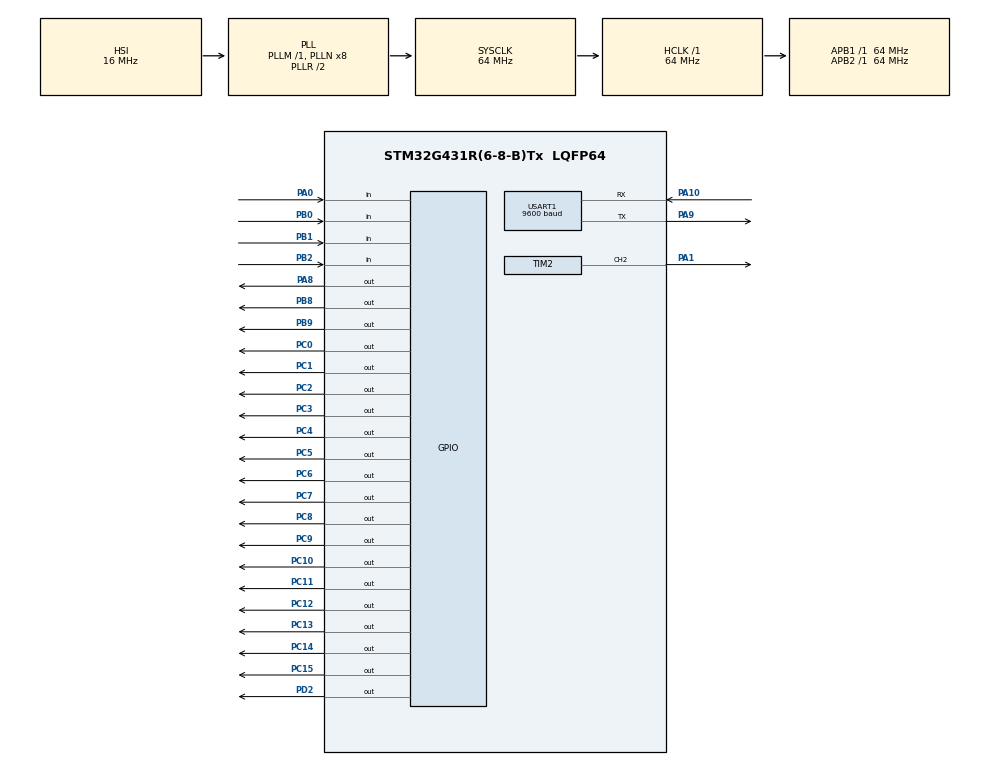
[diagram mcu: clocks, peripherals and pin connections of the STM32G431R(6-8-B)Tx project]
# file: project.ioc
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Mcu.Family=STM32G4
Mcu.Name=STM32G431R(6-8-B)Tx
Mcu.Package=LQFP64
NVIC.PriorityGroup=NVIC_PRIORITYGROUP_4
NVIC.USART1_IRQn=true\:0\:0\:false\:false\:true\:true\:true
PA0.GPIO_PuPd=GPIO_PULLUP
PA0.Signal=GPIO_Input
PA1.Signal=S_TIM2_CH2
PA10.Mode=Asynchronous
PA10.Signal=USART1_RX
PA8.Signal=GPIO_Output
PA9.Mode=Asynchronous
PA9.Signal=USART1_TX
PB0.GPIO_PuPd=GPIO_PULLUP
PB0.Signal=GPIO_Input
PB1.GPIO_PuPd=GPIO_PULLUP
PB1.Signal=GPIO_Input
PB2.GPIO_PuPd=GPIO_PULLUP
PB2.Signal=GPIO_Input
PB8-BOOT0.Signal=GPIO_Output
PB9.Signal=GPIO_Output
PC0.Signal=GPIO_Output
PC1.Signal=GPIO_Output
PC10.Signal=GPIO_Output
PC11.Signal=GPIO_Output
PC12.Signal=GPIO_Output
PC13.Signal=GPIO_Output
PC14-OSC32_IN.Signal=GPIO_Output
PC15-OSC32_OUT.Signal=GPIO_Output
PC2.Signal=GPIO_Output
PC3.Signal=GPIO_Output
PC4.Signal=GPIO_Output
PC5.Signal=GPIO_Output
PC6.Signal=GPIO_Output
PC7.Signal=GPIO_Output
PC8.Signal=GPIO_Output
PC9.Signal=GPIO_Output
PD2.Signal=GPIO_Output
PF0-OSC_IN.Mode=HSE-External-Oscillator
PF0-OSC_IN.Signal=RCC_OSC_IN
PF1-OSC_OUT.Mode=HSE-External-Oscillator
PF1-OSC_OUT.Signal=RCC_OSC_OUT
ProjectManager.HeapSize=0x200
ProjectManager.StackSize=0x400
ProjectManager.TargetToolchain=MDK-ARM V5.32
RCC.ADC12Freq_Value=64000000
RCC.AHBFreq_Value=64000000
RCC.APB1Freq_Value=64000000
RCC.APB1TimFreq_Value=64000000
RCC.APB2Freq_Value=64000000
RCC.APB2TimFreq_Value=64000000
RCC.CortexFreq_Value=64000000
RCC.EXTERNAL_CLOCK_VALUE=12288000
RCC.HCLKFreq_Value=64000000
RCC.HSE_VALUE=8000000
RCC.HSI48_VALUE=48000000
RCC.HSI_VALUE=16000000
RCC.LSE_VALUE=32768
RCC.SYSCLKFreq_VALUE=64000000
RCC.SYSCLKSource=RCC_SYSCLKSOURCE_PLLCLK
RCC.USBFreq_Value=64000000
RCC.VCOOutputFreq_Value=128000000
SH.S_TIM2_CH2.0=TIM2_CH2,PWM Generation2 CH2
TIM2.Channel-PWM\ Generation2\ CH2=TIM_CHANNEL_2
TIM2.PeriodNoDither=500-1
TIM2.Prescaler=64-1
USART1.BaudRate=9600
USART1.VirtualMode-Asynchronous=VM_ASYNC
VP_SYS_VS_DBSignals.Mode=DisableDeadBatterySignals
VP_TIM2_VS_ClockSourceINT.Mode=Internal
board=custom

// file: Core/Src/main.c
/* USER CODE BEGIN Header */
/**
  ******************************************************************************
  * @file           : main.c
  * @brief          : Main program body
  ******************************************************************************
  * @attention
  *
  * Copyright (c) 2022 STMicroelectronics.
  * All rights reserved.
  *
  * This software is licensed under terms that can be found in the LICENSE file
  * in the root directory of this software component.
  * If no LICENSE file comes with this software, it is provided AS-IS.
  *
  ******************************************************************************
  */
/* USER CODE END Header */
#include "main.h"

TIM_HandleTypeDef htim2;

UART_HandleTypeDef huart1;

/* USER CODE BEGIN PV */
extern char rec[1];
/* USER CODE END PV */

void SystemClock_Config(void);
static void MX_GPIO_Init(void);
static void MX_TIM2_Init(void);
static void MX_USART1_UART_Init(void);

int main(void)
{

  /* MCU Configuration--------------------------------------------------------*/

  /* Reset of all peripherals, Initializes the Flash interface and the Systick. */
  HAL_Init();

  /* Configure the system clock */
  SystemClock_Config();

  /* Initialize all configured peripherals */
  MX_GPIO_Init();
  MX_TIM2_Init();
  MX_USART1_UART_Init();
  /* USER CODE BEGIN 2 */
	I2CInit();
	//EE_init();
	HAL_TIM_PWM_Start(&htim2,TIM_CHANNEL_2);
	LCD_Init();
	LCD_SetTextColor(White);
	LCD_SetBackColor(Black);
	HAL_UART_Receive_IT(&huart1,(unsigned char*)rec,1);
  /* USER CODE END 2 */

  /* Infinite loop */
  while (1)
  {

    /* USER CODE BEGIN 3 */
		EE_rd();
		key_menu();
		lcd_menu();
		pwm_main();
		led_main();
  }
  /* USER CODE END 3 */
}

void SystemClock_Config(void)
{
  RCC_OscInitTypeDef RCC_OscInitStruct = {0};
  RCC_ClkInitTypeDef RCC_ClkInitStruct = {0};

  /** Configure the main internal regulator output voltage
  */
  HAL_PWREx_ControlVoltageScaling(PWR_REGULATOR_VOLTAGE_SCALE1);
  /** Initializes the RCC Oscillators according to the specified parameters
  * in the RCC_OscInitTypeDef structure.
  */
  RCC_OscInitStruct.OscillatorType = RCC_OSCILLATORTYPE_HSI;
  RCC_OscInitStruct.HSIState = RCC_HSI_ON;
  RCC_OscInitStruct.HSICalibrationValue = RCC_HSICALIBRATION_DEFAULT;
  RCC_OscInitStruct.PLL.PLLState = RCC_PLL_ON;
  RCC_OscInitStruct.PLL.PLLSource = RCC_PLLSOURCE_HSI;
  RCC_OscInitStruct.PLL.PLLM = RCC_PLLM_DIV1;
  RCC_OscInitStruct.PLL.PLLN = 8;
  RCC_OscInitStruct.PLL.PLLP = RCC_PLLP_DIV2;
  RCC_OscInitStruct.PLL.PLLQ = RCC_PLLQ_DIV2;
  RCC_OscInitStruct.PLL.PLLR = RCC_PLLR_DIV2;
  if (HAL_RCC_OscConfig(&RCC_OscInitStruct) != HAL_OK)
  {
    Error_Handler();
  }
  /** Initializes the CPU, AHB and APB buses clocks
  */
  RCC_ClkInitStruct.ClockType = RCC_CLOCKTYPE_HCLK|RCC_CLOCKTYPE_SYSCLK
                              |RCC_CLOCKTYPE_PCLK1|RCC_CLOCKTYPE_PCLK2;
  RCC_ClkInitStruct.SYSCLKSource = RCC_SYSCLKSOURCE_PLLCLK;
  RCC_ClkInitStruct.AHBCLKDivider = RCC_SYSCLK_DIV1;
  RCC_ClkInitStruct.APB1CLKDivider = RCC_HCLK_DIV1;
  RCC_ClkInitStruct.APB2CLKDivider = RCC_HCLK_DIV1;

  if (HAL_RCC_ClockConfig(&RCC_ClkInitStruct, FLASH_LATENCY_1) != HAL_OK)
  {
    Error_Handler();
  }
}

static void MX_TIM2_Init(void)
{

  TIM_ClockConfigTypeDef sClockSourceConfig = {0};
  TIM_MasterConfigTypeDef sMasterConfig = {0};
  TIM_OC_InitTypeDef sConfigOC = {0};

  htim2.Instance = TIM2;
  htim2.Init.Prescaler = 64-1;
  htim2.Init.CounterMode = TIM_COUNTERMODE_UP;
  htim2.Init.Period = 499;
  htim2.Init.ClockDivision = TIM_CLOCKDIVISION_DIV1;
  htim2.Init.AutoReloadPreload = TIM_AUTORELOAD_PRELOAD_DISABLE;
  if (HAL_TIM_Base_Init(&htim2) != HAL_OK)
  {
    Error_Handler();
  }
  sClockSourceConfig.ClockSource = TIM_CLOCKSOURCE_INTERNAL;
  if (HAL_TIM_ConfigClockSource(&htim2, &sClockSourceConfig) != HAL_OK)
  {
    Error_Handler();
  }
  if (HAL_TIM_PWM_Init(&htim2) != HAL_OK)
  {
    Error_Handler();
  }
  sMasterConfig.MasterOutputTrigger = TIM_TRGO_RESET;
  sMasterConfig.MasterSlaveMode = TIM_MASTERSLAVEMODE_DISABLE;
  if (HAL_TIMEx_MasterConfigSynchronization(&htim2, &sMasterConfig) != HAL_OK)
  {
    Error_Handler();
  }
  sConfigOC.OCMode = TIM_OCMODE_PWM1;
  sConfigOC.Pulse = 0;
  sConfigOC.OCPolarity = TIM_OCPOLARITY_HIGH;
  sConfigOC.OCFastMode = TIM_OCFAST_DISABLE;
  if (HAL_TIM_PWM_ConfigChannel(&htim2, &sConfigOC, TIM_CHANNEL_2) != HAL_OK)
  {
    Error_Handler();
  }
  HAL_TIM_MspPostInit(&htim2);

}

static void MX_USART1_UART_Init(void)
{

  huart1.Instance = USART1;
  huart1.Init.BaudRate = 9600;
  huart1.Init.WordLength = UART_WORDLENGTH_8B;
  huart1.Init.StopBits = UART_STOPBITS_1;
  huart1.Init.Parity = UART_PARITY_NONE;
  huart1.Init.Mode = UART_MODE_TX_RX;
  huart1.Init.HwFlowCtl = UART_HWCONTROL_NONE;
  huart1.Init.OverSampling = UART_OVERSAMPLING_16;
  huart1.Init.OneBitSampling = UART_ONE_BIT_SAMPLE_DISABLE;
  huart1.Init.ClockPrescaler = UART_PRESCALER_DIV1;
  huart1.AdvancedInit.AdvFeatureInit = UART_ADVFEATURE_NO_INIT;
  if (HAL_UART_Init(&huart1) != HAL_OK)
  {
    Error_Handler();
  }
  if (HAL_UARTEx_SetTxFifoThreshold(&huart1, UART_TXFIFO_THRESHOLD_1_8) != HAL_OK)
  {
    Error_Handler();
  }
  if (HAL_UARTEx_SetRxFifoThreshold(&huart1, UART_RXFIFO_THRESHOLD_1_8) != HAL_OK)
  {
    Error_Handler();
  }
  if (HAL_UARTEx_DisableFifoMode(&huart1) != HAL_OK)
  {
    Error_Handler();
  }

}

static void MX_GPIO_Init(void)
{
  GPIO_InitTypeDef GPIO_InitStruct = {0};

  /* GPIO Ports Clock Enable */
  __HAL_RCC_GPIOC_CLK_ENABLE();
  __HAL_RCC_GPIOF_CLK_ENABLE();
  __HAL_RCC_GPIOA_CLK_ENABLE();
  __HAL_RCC_GPIOB_CLK_ENABLE();
  __HAL_RCC_GPIOD_CLK_ENABLE();

  /*Configure GPIO pin Output Level */
  HAL_GPIO_WritePin(GPIOC, GPIO_PIN_13|GPIO_PIN_14|GPIO_PIN_15|GPIO_PIN_0
                          |GPIO_PIN_1|GPIO_PIN_2|GPIO_PIN_3|GPIO_PIN_4
                          |GPIO_PIN_5|GPIO_PIN_6|GPIO_PIN_7|GPIO_PIN_8
                          |GPIO_PIN_9|GPIO_PIN_10|GPIO_PIN_11|GPIO_PIN_12, GPIO_PIN_RESET);

  /*Configure GPIO pin Output Level */
  HAL_GPIO_WritePin(GPIOA, GPIO_PIN_8, GPIO_PIN_RESET);

  /*Configure GPIO pin Output Level */
  HAL_GPIO_WritePin(GPIOD, GPIO_PIN_2, GPIO_PIN_RESET);

  /*Configure GPIO pin Output Level */
  HAL_GPIO_WritePin(GPIOB, GPIO_PIN_8|GPIO_PIN_9, GPIO_PIN_RESET);

  /*Configure GPIO pins : PC13 PC14 PC15 PC0
                           PC1 PC2 PC3 PC4
                           PC5 PC6 PC7 PC8
                           PC9 PC10 PC11 PC12 */
  GPIO_InitStruct.Pin = GPIO_PIN_13|GPIO_PIN_14|GPIO_PIN_15|GPIO_PIN_0
                          |GPIO_PIN_1|GPIO_PIN_2|GPIO_PIN_3|GPIO_PIN_4
                          |GPIO_PIN_5|GPIO_PIN_6|GPIO_PIN_7|GPIO_PIN_8
                          |GPIO_PIN_9|GPIO_PIN_10|GPIO_PIN_11|GPIO_PIN_12;
  GPIO_InitStruct.Mode = GPIO_MODE_OUTPUT_PP;
  GPIO_InitStruct.Pull = GPIO_NOPULL;
  GPIO_InitStruct.Speed = GPIO_SPEED_FREQ_LOW;
  HAL_GPIO_Init(GPIOC, &GPIO_InitStruct);

  /*Configure GPIO pin : PA0 */
  GPIO_InitStruct.Pin = GPIO_PIN_0;
  GPIO_InitStruct.Mode = GPIO_MODE_INPUT;
  GPIO_InitStruct.Pull = GPIO_PULLUP;
  HAL_GPIO_Init(GPIOA, &GPIO_InitStruct);

  /*Configure GPIO pins : PB0 PB1 PB2 */
  GPIO_InitStruct.Pin = GPIO_PIN_0|GPIO_PIN_1|GPIO_PIN_2;
  GPIO_InitStruct.Mode = GPIO_MODE_INPUT;
  GPIO_InitStruct.Pull = GPIO_PULLUP;
  HAL_GPIO_Init(GPIOB, &GPIO_InitStruct);

  /*Configure GPIO pin : PA8 */
  GPIO_InitStruct.Pin = GPIO_PIN_8;
  GPIO_InitStruct.Mode = GPIO_MODE_OUTPUT_PP;
  GPIO_InitStruct.Pull = GPIO_NOPULL;
  GPIO_InitStruct.Speed = GPIO_SPEED_FREQ_LOW;
  HAL_GPIO_Init(GPIOA, &GPIO_InitStruct);

  /*Configure GPIO pin : PD2 */
  GPIO_InitStruct.Pin = GPIO_PIN_2;
  GPIO_InitStruct.Mode = GPIO_MODE_OUTPUT_PP;
  GPIO_InitStruct.Pull = GPIO_NOPULL;
  GPIO_InitStruct.Speed = GPIO_SPEED_FREQ_LOW;
  HAL_GPIO_Init(GPIOD, &GPIO_InitStruct);

  /*Configure GPIO pins : PB8 PB9 */
  GPIO_InitStruct.Pin = GPIO_PIN_8|GPIO_PIN_9;
  GPIO_InitStruct.Mode = GPIO_MODE_OUTPUT_PP;
  GPIO_InitStruct.Pull = GPIO_NOPULL;
  GPIO_InitStruct.Speed = GPIO_SPEED_FREQ_LOW;
  HAL_GPIO_Init(GPIOB, &GPIO_InitStruct);

}

void Error_Handler(void)
{
  __disable_irq();
  while (1)
  {
  }
}
